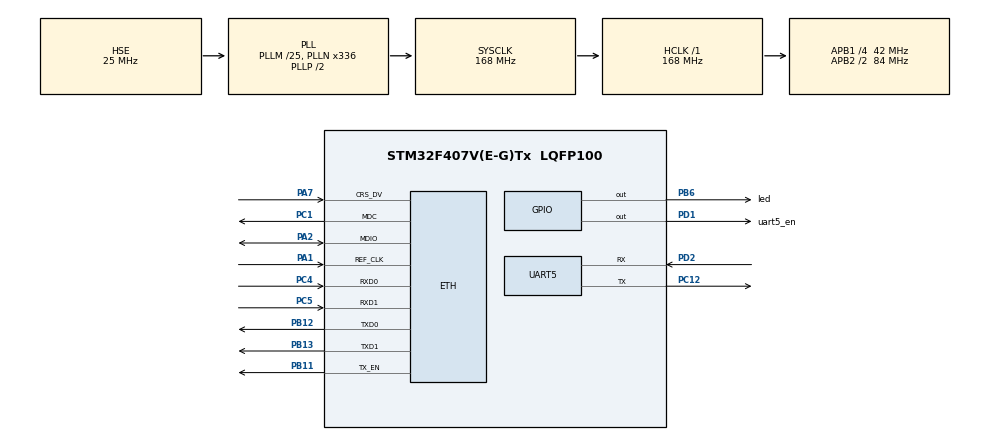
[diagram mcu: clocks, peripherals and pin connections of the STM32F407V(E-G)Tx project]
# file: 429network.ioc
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ETH.ChecksumMode=ETH_CHECKSUM_BY_HARDWARE
ETH.MediaInterface=ETH_MEDIA_INTERFACE_RMII
ETH.PHY_Name_RMII=DP83848_PHY_ADDRESS
ETH.PhyAddress=1
FREERTOS.Tasks01=defaultTask,24,256,StartDefaultTask,As weak,NULL,Dynamic,NULL,NULL;myTask02,8,256,StartTask02,As weak,NULL,Dynamic,NULL,NULL
FREERTOS.configTICK_RATE_HZ=200
LWIP.GATEWAY_ADDRESS=192.168.001.001
LWIP.IP_ADDRESS=192.168.001.150
LWIP.LWIP_DHCP=0
LWIP.LWIP_NETIF_STATUS_CALLBACK=1
LWIP.LWIP_UDP=0
LWIP.NETMASK_ADDRESS=255.255.255.000
LWIP.Version=v2.1.2_Cube
Mcu.Family=STM32F4
Mcu.Name=STM32F407V(E-G)Tx
Mcu.Package=LQFP100
NVIC.ETH_IRQn=true\:6\:0\:true\:false\:true\:false\:false\:true
NVIC.ETH_WKUP_IRQn=true\:6\:0\:true\:false\:true\:false\:true\:true
NVIC.PriorityGroup=NVIC_PRIORITYGROUP_4
NVIC.TIM4_IRQn=true\:0\:0\:false\:false\:true\:false\:false\:true
NVIC.TimeBase=TIM4_IRQn
NVIC.TimeBaseIP=TIM4
PA1.Mode=RMII
PA1.Signal=ETH_REF_CLK
PA2.Mode=RMII
PA2.Signal=ETH_MDIO
PA7.Mode=RMII
PA7.Signal=ETH_CRS_DV
PB11.Mode=RMII
PB11.Signal=ETH_TX_EN
PB12.Mode=RMII
PB12.Signal=ETH_TXD0
PB13.Mode=RMII
PB13.Signal=ETH_TXD1
PB6.GPIO_Label=led
PB6.Signal=GPIO_Output
PC1.Mode=RMII
PC1.Signal=ETH_MDC
PC12.Mode=Asynchronous
PC12.Signal=UART5_TX
PC4.Mode=RMII
PC4.Signal=ETH_RXD0
PC5.Mode=RMII
PC5.Signal=ETH_RXD1
PD1.GPIO_Label=uart5_en
PD1.Signal=GPIO_Output
PD2.Mode=Asynchronous
PD2.Signal=UART5_RX
PH0-OSC_IN.Mode=HSE-External-Oscillator
PH0-OSC_IN.Signal=RCC_OSC_IN
PH1-OSC_OUT.Mode=HSE-External-Oscillator
PH1-OSC_OUT.Signal=RCC_OSC_OUT
ProjectManager.HeapSize=0x200
ProjectManager.StackSize=0x400
ProjectManager.TargetToolchain=MDK-ARM V5
RCC.48MHZClocksFreq_Value=84000000
RCC.AHBFreq_Value=168000000
RCC.APB1CLKDivider=RCC_HCLK_DIV4
RCC.APB1Freq_Value=42000000
RCC.APB1TimFreq_Value=84000000
RCC.APB2CLKDivider=RCC_HCLK_DIV2
RCC.APB2Freq_Value=84000000
RCC.APB2TimFreq_Value=168000000
RCC.CortexFreq_Value=168000000
RCC.HCLKFreq_Value=168000000
RCC.HSE_VALUE=25000000
RCC.HSI_VALUE=16000000
RCC.LSE_VALUE=32768
RCC.PLLM=25
RCC.PLLN=336
RCC.PLLSourceVirtual=RCC_PLLSOURCE_HSE
RCC.SYSCLKFreq_VALUE=168000000
RCC.SYSCLKSource=RCC_SYSCLKSOURCE_PLLCLK
RCC.VCOOutputFreq_Value=336000000
UART5.VirtualMode=Asynchronous
VP_FREERTOS_VS_CMSIS_V2.Mode=CMSIS_V2
VP_LWIP_VS_Enabled.Mode=Enabled
VP_SYS_VS_tim4.Mode=TIM4
board=custom

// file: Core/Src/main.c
/* USER CODE BEGIN Header */
/**
  ******************************************************************************
  * @file           : main.c
  * @brief          : Main program body
  ******************************************************************************
  * @attention
  *
  * <h2><center>&copy; Copyright (c) 2022 STMicroelectronics.
  * All rights reserved.</center></h2>
  *
  * This software component is licensed by ST under BSD 3-Clause license,
  * the "License"; You may not use this file except in compliance with the
  * License. You may obtain a copy of the License at:
  *                        opensource.org/licenses/BSD-3-Clause
  *
  ******************************************************************************
  */
/* USER CODE END Header */
#include "main.h"
#include "cmsis_os.h"
#include "lwip.h"
#include "usart.h"
#include "gpio.h"

void SystemClock_Config(void);
void MX_FREERTOS_Init(void);

int main(void)
{

  /* MCU Configuration--------------------------------------------------------*/

  /* Reset of all peripherals, Initializes the Flash interface and the Systick. */
  HAL_Init();

  /* Configure the system clock */
  SystemClock_Config();

  /* Initialize all configured peripherals */
  MX_GPIO_Init();
  MX_UART5_Init();

  /* Init scheduler */
  osKernelInitialize();  /* Call init function for freertos objects (in freertos.c) */
  MX_FREERTOS_Init();
  /* Start scheduler */
  osKernelStart();

  /* We should never get here as control is now taken by the scheduler */
  /* Infinite loop */
  while (1)
  {

  }
}

void SystemClock_Config(void)
{
  RCC_OscInitTypeDef RCC_OscInitStruct = {0};
  RCC_ClkInitTypeDef RCC_ClkInitStruct = {0};

  /** Configure the main internal regulator output voltage
  */
  __HAL_RCC_PWR_CLK_ENABLE();
  __HAL_PWR_VOLTAGESCALING_CONFIG(PWR_REGULATOR_VOLTAGE_SCALE1);
  /** Initializes the RCC Oscillators according to the specified parameters
  * in the RCC_OscInitTypeDef structure.
  */
  RCC_OscInitStruct.OscillatorType = RCC_OSCILLATORTYPE_HSE;
  RCC_OscInitStruct.HSEState = RCC_HSE_ON;
  RCC_OscInitStruct.PLL.PLLState = RCC_PLL_ON;
  RCC_OscInitStruct.PLL.PLLSource = RCC_PLLSOURCE_HSE;
  RCC_OscInitStruct.PLL.PLLM = 25;
  RCC_OscInitStruct.PLL.PLLN = 336;
  RCC_OscInitStruct.PLL.PLLP = RCC_PLLP_DIV2;
  RCC_OscInitStruct.PLL.PLLQ = 4;
  if (HAL_RCC_OscConfig(&RCC_OscInitStruct) != HAL_OK)
  {
    Error_Handler();
  }
  /** Initializes the CPU, AHB and APB buses clocks
  */
  RCC_ClkInitStruct.ClockType = RCC_CLOCKTYPE_HCLK|RCC_CLOCKTYPE_SYSCLK
                              |RCC_CLOCKTYPE_PCLK1|RCC_CLOCKTYPE_PCLK2;
  RCC_ClkInitStruct.SYSCLKSource = RCC_SYSCLKSOURCE_PLLCLK;
  RCC_ClkInitStruct.AHBCLKDivider = RCC_SYSCLK_DIV1;
  RCC_ClkInitStruct.APB1CLKDivider = RCC_HCLK_DIV4;
  RCC_ClkInitStruct.APB2CLKDivider = RCC_HCLK_DIV2;

  if (HAL_RCC_ClockConfig(&RCC_ClkInitStruct, FLASH_LATENCY_5) != HAL_OK)
  {
    Error_Handler();
  }
}

void HAL_TIM_PeriodElapsedCallback(TIM_HandleTypeDef *htim)
{
  if (htim->Instance == TIM4) {
    HAL_IncTick();
  }
}

void Error_Handler(void)
{
}

/************************ (C) COPYRIGHT STMicroelectronics *****END OF FILE****/

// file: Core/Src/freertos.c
/* USER CODE BEGIN Header */
/**
  ******************************************************************************
  * File Name          : freertos.c
  * Description        : Code for freertos applications
  ******************************************************************************
  * @attention
  *
  * <h2><center>&copy; Copyright (c) 2022 STMicroelectronics.
  * All rights reserved.</center></h2>
  *
  * This software component is licensed by ST under Ultimate Liberty license
  * SLA0044, the "License"; You may not use this file except in compliance with
  * the License. You may obtain a copy of the License at:
  *                             www.st.com/SLA0044
  *
  ******************************************************************************
  */
/* USER CODE END Header */

#include "FreeRTOS.h"
#include "task.h"
#include "main.h"
#include "cmsis_os.h"

/* Definitions for defaultTask */
osThreadId_t defaultTaskHandle;
const osThreadAttr_t defaultTask_attributes = {
  .name = "defaultTask",
  .priority = (osPriority_t) osPriorityNormal,
  .stack_size = 256 * 4
};
/* Definitions for myTask02 */
osThreadId_t myTask02Handle;
const osThreadAttr_t myTask02_attributes = {
  .name = "myTask02",
  .priority = (osPriority_t) osPriorityLow,
  .stack_size = 256 * 4
};

void StartDefaultTask(void *argument);
void StartTask02(void *argument);

extern void MX_LWIP_Init(void);
void MX_FREERTOS_Init(void); /* (MISRA C 2004 rule 8.1) */

void MX_FREERTOS_Init(void) {

  /* Create the thread(s) */
  /* creation of defaultTask */
  defaultTaskHandle = osThreadNew(StartDefaultTask, NULL, &defaultTask_attributes);

  /* creation of myTask02 */
  myTask02Handle = osThreadNew(StartTask02, NULL, &myTask02_attributes);

}

__weak void StartDefaultTask(void *argument)
{
  /* init code for LWIP */
  MX_LWIP_Init();
  for(;;)
  {
    osDelay(1);
  }
}

__weak void StartTask02(void *argument)
{
  /* USER CODE BEGIN StartTask02 */
  /* Infinite loop */
  for(;;)
  {
    osDelay(100);
	  HAL_GPIO_TogglePin(led_GPIO_Port,led_Pin);
  }
  /* USER CODE END StartTask02 */
}

/************************ (C) COPYRIGHT STMicroelectronics *****END OF FILE****/
